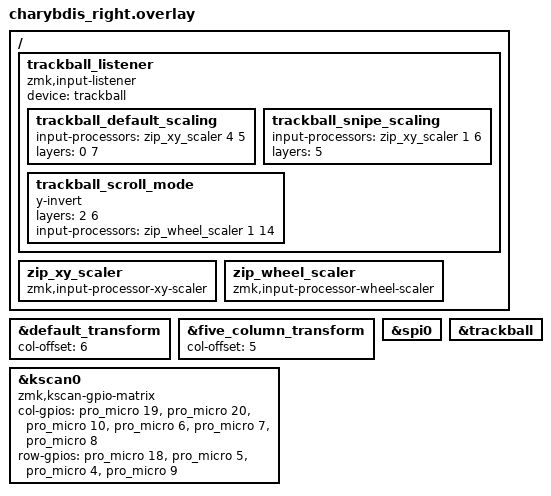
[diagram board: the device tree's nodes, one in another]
#include "charybdis.dtsi"
#include "charybdis_pmw3610.dtsi"

// The matrix transform is 6 columns over because the left half is 6 columns wide.
&default_transform {
	col-offset = <6>;
};

&five_column_transform {
	col-offset = <5>;
};

&kscan0 {
	compatible = "zmk,kscan-gpio-matrix";
	
	col-gpios
		= <&pro_micro 19 (GPIO_ACTIVE_HIGH | GPIO_PULL_DOWN)>
		, <&pro_micro 20 (GPIO_ACTIVE_HIGH | GPIO_PULL_DOWN)>
		, <&pro_micro 10 (GPIO_ACTIVE_HIGH | GPIO_PULL_DOWN)>
		, <&pro_micro 6 (GPIO_ACTIVE_HIGH | GPIO_PULL_DOWN)>
		, <&pro_micro 7 (GPIO_ACTIVE_HIGH | GPIO_PULL_DOWN)>
		, <&pro_micro 8 (GPIO_ACTIVE_HIGH | GPIO_PULL_DOWN)>
		;

	row-gpios
		= <&pro_micro 18 GPIO_ACTIVE_HIGH>
		, <&pro_micro 5 GPIO_ACTIVE_HIGH>
		, <&pro_micro 4 GPIO_ACTIVE_HIGH>
		, <&pro_micro 9 GPIO_ACTIVE_HIGH>
		;
};

&spi0 {
    status = "okay";
};

&trackball {
    status = "okay";
};

// This block defines the full trackball functionality
/ {
    trackball_listener {
        compatible = "zmk,input-listener";
        device = <&trackball>;
        
        // --- STANDARD MOVEMENT MODE (Layer 0, 7) ---
        // Uses the defined zip_xy_scaler node with a scaling value of 4/5
        trackball_default_scaling: trackball_default_scaling {
            input-processors = <&zip_xy_scaler 4 5>;
            layers = <0 7>;
        };

        // --- SNIPE MODE (Layer 5) ---
        // Uses the defined zip_xy_scaler node with a slower scaling value of 1/6
        trackball_snipe_scaling: trackball_snipe_scaling {
            input-processors = <&zip_xy_scaler 1 6>;
            layers = <5>;
        };

        // --- SCROLL MODE (Layer 2, 6) ---
        // Uses the defined zip_wheel_scaler node with inverted Y and a 1/14 scale
        trackball_scroll_mode: trackball_scroll_mode {
            y-invert;
            layers = <2 6>;
            input-processors = <&zip_wheel_scaler 1 14>;
        };
    };
};

// Add this block to boards/shields/charybdis-bt/charybdis_right.overlay

/ {
    // Defines the Input Processor node for X/Y movement scaling
    zip_xy_scaler: zip_xy_scaler {
        compatible = "zmk,input-processor-xy-scaler";
        #binding-cells = <2>;
    };

    // Defines the Input Processor node for scroll wheel scaling
    zip_wheel_scaler: zip_wheel_scaler {
        compatible = "zmk,input-processor-wheel-scaler";
        #binding-cells = <2>;
    };
};
